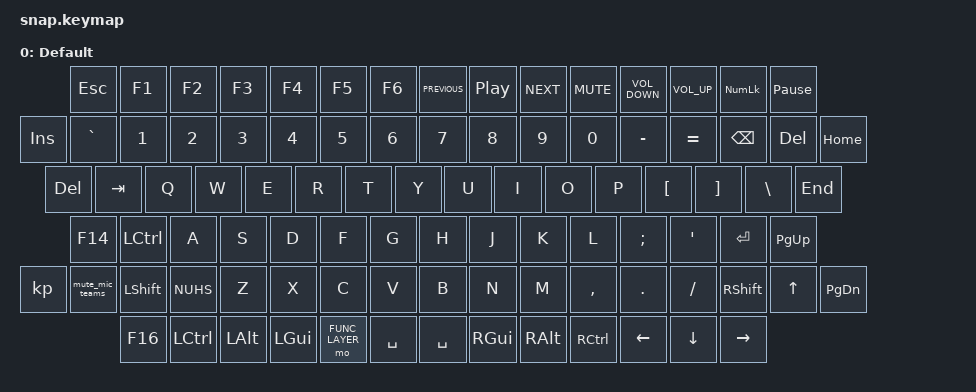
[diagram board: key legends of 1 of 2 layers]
/*
 * Copyright (c) 2022 The ZMK Contributors
 *
 * SPDX-License-Identifier: MIT
 */

#include <behaviors.dtsi>
#include <dt-bindings/zmk/keys.h>
#include <dt-bindings/zmk/bt.h>


//CUSTOM VARIABLES
#define DEFAULT 0
#define FUNC_LAYER 1

/ {
	macros {
		mute_mic_teams: mute_mic_teams {
			label = "MACRO_mute_mic_teams";
			compatible = "zmk,behaviour-macro";
			#binding-cells = <0>;
			bindings
				= <&macro_press &kp LSHIFT &kp LGUI>
				, <&macro_tap &kp M>
				, <&macro_release &kp LSHIFT &kp LGUI>
				;
		};
	};

	keymap {
		compatible = "zmk,keymap";

		default_layer {
			label = "Default";
			bindings = <
             &kp ESC     	&kp F1   	&kp F2   	&kp F3   	&kp F4   	&kp F5   &kp F6     &kp C_PREVIOUS   	&kp C_PLAY_PAUSE   	&kp C_NEXT    	&kp K_MUTE      &kp C_VOLUME_DOWN      &kp C_VOLUME_UP     &kp KP_NUM   &kp PAUSE_BREAK
&kp INSERT   &kp GRAVE   	&kp N1   	&kp N2   	&kp N3   	&kp N4   	&kp N5   &kp N6     &kp N7   &kp N8   &kp N9    &kp N0   &kp MINUS   &kp EQUAL   &kp BSPC     &kp DEL    &kp HOME
&kp DELETE      &kp TAB     	&kp Q    	&kp W    	&kp E    	&kp R             &kp T      &kp Y    &kp U    &kp I     &kp O    &kp P       &kp LBKT    &kp RBKT     &kp BSLH   &kp END
&kp F14      &kp LCTRL    	&kp A    	&kp S   	&kp D    	&kp F             &kp G      &kp H    &kp J    &kp K     &kp L    &kp SEMI    &kp SQT     &kp RET                 &kp PG_UP
&kp &mute_mic_teams      &kp LSHFT   	&kp NUHS 	&kp Z    	&kp X    	&kp C    	&kp V    &kp B      &kp N    &kp M    &kp COMMA &kp DOT  &kp FSLH    &kp RSHFT                &kp UP     &kp PG_DN
&kp F16      &kp LCTRL   	&kp LALT 	&kp LGUI          &mo FUNC_LAYER            &kp SPACE    &kp SPACE                   &kp RGUI    &kp RALT    &kp RCTRL   &kp LEFT     &kp DOWN   &kp RIGHT
			>;
		};

		function_layer {
			label = "Function";
			bindings = <
             &bootloader 	&trans   		&trans   		&trans   		&trans   	&trans   	&trans   	&kp F7   &kp F8   &kp F9    &kp F10  &kp F11     &kp F12		&bt BT_CLR       &bootloader
&trans     &trans      	&bt BT_SEL 0   	&bt BT_SEL 1   	&bt BT_SEL 2   	&trans   &trans   &trans     &trans   &trans   &trans   &trans    &trans      &trans      &trans       &trans     &trans
&trans       &trans      	&trans   		&trans   		&trans   		&trans            &trans     &trans   &trans   &trans   &trans    &trans      &trans      &trans       &trans     &trans 
&trans       &trans      	&trans  		&trans   		&trans   		&trans            &trans     &trans   &trans   &trans   &trans    &trans      &trans                   &trans     &trans
&trans       &trans      	&trans   		&trans   		&trans   		&trans   &trans   &trans     &trans   &trans   &trans   &trans    &trans          &trans &trans &trans
&sys_reset       &trans      	&trans   		&trans            &trans           &trans       &trans                    &trans    &trans  &trans  &trans &trans &trans
			>;
		};
	};
};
